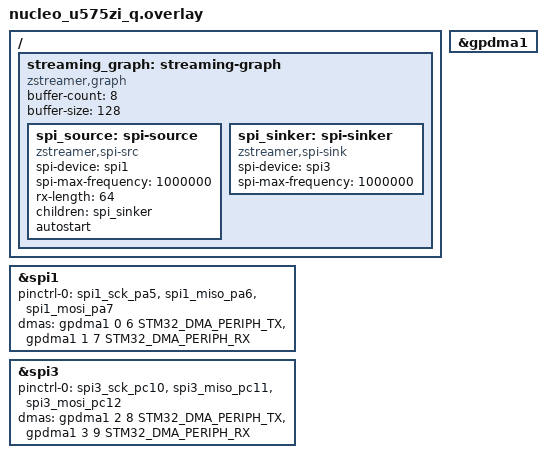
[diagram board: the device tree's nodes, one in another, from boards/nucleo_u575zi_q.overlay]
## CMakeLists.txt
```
# Copyright (c) 2026 sharonthecreator
# SPDX-License-Identifier: Apache-2.0

cmake_minimum_required(VERSION 3.20.0)
find_package(Zephyr REQUIRED HINTS $ENV{ZEPHYR_BASE})
project(spi2spi)

target_sources(app PRIVATE src/main.c)
```

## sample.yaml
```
# Copyright (c) 2026 sharonthecreator
# SPDX-License-Identifier: Apache-2.0

sample:
  name: SPI-to-SPI relay
  description: |
    Reads data from one SPI bus and writes it to another using a
    zstreamer graph with spi-src and spi-sink nodes.
tests:
  sample.zstreamer.spi2spi:
    tags: zstreamer spi
    platform_allow: nucleo_u575zi_q
```

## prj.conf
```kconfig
# Copyright (c) 2026 sharonthecreator
# SPDX-License-Identifier: Apache-2.0

CONFIG_ZSTREAMER=y
CONFIG_ZSTREAMER_SPI_SRC=y
CONFIG_ZSTREAMER_SPI_SINK=y
CONFIG_SPI=y
CONFIG_LOG=y
# Enable SPI async/DMA API for efficient transfers
CONFIG_SPI_ASYNC=y
CONFIG_DMA=y
```

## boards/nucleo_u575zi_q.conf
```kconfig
# Copyright (c) 2026 sharonthecreator
# SPDX-License-Identifier: Apache-2.0

# Enable SPI async/DMA API for efficient transfers
CONFIG_SPI_ASYNC=y
CONFIG_DMA=y
```

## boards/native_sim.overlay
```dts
/*
 * Copyright (c) 2026 sharonthecreator
 * SPDX-License-Identifier: Apache-2.0
 *
 * SPI-to-SPI relay on native_sim using emulated SPI.
 */

/ {
	spi_src: spi-emul-src {
		compatible = "zephyr,spi-emul-controller";
		#address-cells = <1>;
		#size-cells = <0>;
		status = "okay";
	};

	spi_sink: spi-emul-sink {
		compatible = "zephyr,spi-emul-controller";
		#address-cells = <1>;
		#size-cells = <0>;
		status = "okay";
	};

	streaming_graph: streaming-graph {
		compatible = "zstreamer,graph";
		buffer-count = <8>;
		buffer-size = <128>;

		spi_source: spi-source {
			compatible = "zstreamer,zstsrc-spi";
			spi-device = <&spi_src>;
			spi-max-frequency = <1000000>;
			rx-length = <64>;
			children = <&spi_sinker>;
		};

		spi_sinker: spi-sinker {
			compatible = "zstreamer,zstsink-spi";
			spi-device = <&spi_sink>;
			spi-max-frequency = <1000000>;
		};
	};
};
```

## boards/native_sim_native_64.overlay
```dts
/*
 * Copyright (c) 2026 sharonthecreator
 * SPDX-License-Identifier: Apache-2.0
 *
 * SPI-to-SPI relay on native_sim using emulated SPI.
 */

/ {
	spi_src: spi-emul-src {
		compatible = "zephyr,spi-emul-controller";
		#address-cells = <1>;
		#size-cells = <0>;
		status = "okay";
	};

	spi_sink: spi-emul-sink {
		compatible = "zephyr,spi-emul-controller";
		#address-cells = <1>;
		#size-cells = <0>;
		status = "okay";
	};

	streaming_graph: streaming-graph {
		compatible = "zstreamer,graph";
		buffer-count = <8>;
		buffer-size = <128>;

		spi_source: spi-source {
			compatible = "zstreamer,spi-src";
			spi-device = <&spi_src>;
			spi-max-frequency = <1000000>;
			rx-length = <64>;
			children = <&spi_sinker>;
			autostart;
		};

		spi_sinker: spi-sinker {
			compatible = "zstreamer,spi-sink";
			spi-device = <&spi_sink>;
			spi-max-frequency = <1000000>;
		};
	};
};
```

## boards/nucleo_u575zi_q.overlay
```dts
/*
 * Copyright (c) 2026 sharonthecreator
 * SPDX-License-Identifier: Apache-2.0
 *
 * SPI-to-SPI relay on Nucleo U575ZI-Q with DMA support.
 *
 * Source: SPI1 (PA5 SCK / PA6 MISO / PA7 MOSI) — Arduino D13/D12/D11
 * Sink:   SPI3 (PC10 SCK / PC11 MISO / PC12 MOSI) — Morpho CN11
 *
 * Connect an SPI slave device to SPI1 to read data;
 * the pipeline writes it out on SPI3.
 *
 * DMA is automatically used when CONFIG_SPI_ASYNC is enabled.
 */

&spi1 {
	status = "okay";
	pinctrl-0 = <&spi1_sck_pa5 &spi1_miso_pa6 &spi1_mosi_pa7>;
	pinctrl-names = "default";
	dmas = <&gpdma1 0 6 STM32_DMA_PERIPH_TX>,
	       <&gpdma1 1 7 STM32_DMA_PERIPH_RX>;
	dma-names = "tx", "rx";
};

&spi3 {
	status = "okay";
	pinctrl-0 = <&spi3_sck_pc10 &spi3_miso_pc11 &spi3_mosi_pc12>;
	pinctrl-names = "default";
	dmas = <&gpdma1 2 8 STM32_DMA_PERIPH_TX>,
	       <&gpdma1 3 9 STM32_DMA_PERIPH_RX>;
	dma-names = "tx", "rx";
};

&gpdma1 {
	status = "okay";
};

/ {
	streaming_graph: streaming-graph {
		compatible = "zstreamer,graph";
		buffer-count = <8>;
		buffer-size = <128>;

		spi_source: spi-source {
			compatible = "zstreamer,spi-src";
			spi-device = <&spi1>;
			spi-max-frequency = <1000000>;
			rx-length = <64>;
			children = <&spi_sinker>;
			autostart;
		};

		spi_sinker: spi-sinker {
			compatible = "zstreamer,spi-sink";
			spi-device = <&spi3>;
			spi-max-frequency = <1000000>;
		};
	};
};
```

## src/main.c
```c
/*
 * Copyright (c) 2026 sharonthecreator
 * SPDX-License-Identifier: Apache-2.0
 */

#include <zephyr/device.h>
#include <zephyr/kernel.h>
#include <zephyr/logging/log.h>

#include <zstreamer/source.h>

LOG_MODULE_REGISTER(spi2spi, LOG_LEVEL_INF);

#define SRC_NODE DT_NODELABEL(spi_source)

int main(void) {
  const struct device *src = DEVICE_DT_GET(SRC_NODE);
  int ret;

  if (!device_is_ready(src)) {
    LOG_ERR("streaming devices not ready");
    return -ENODEV;
  }

  ret = zstreamer_source_start(src);
  if (ret) {
    LOG_ERR("failed to start pipeline: %d", ret);
    return ret;
  }

  LOG_INF("spi2spi pipeline running");
  return 0;
}
```
